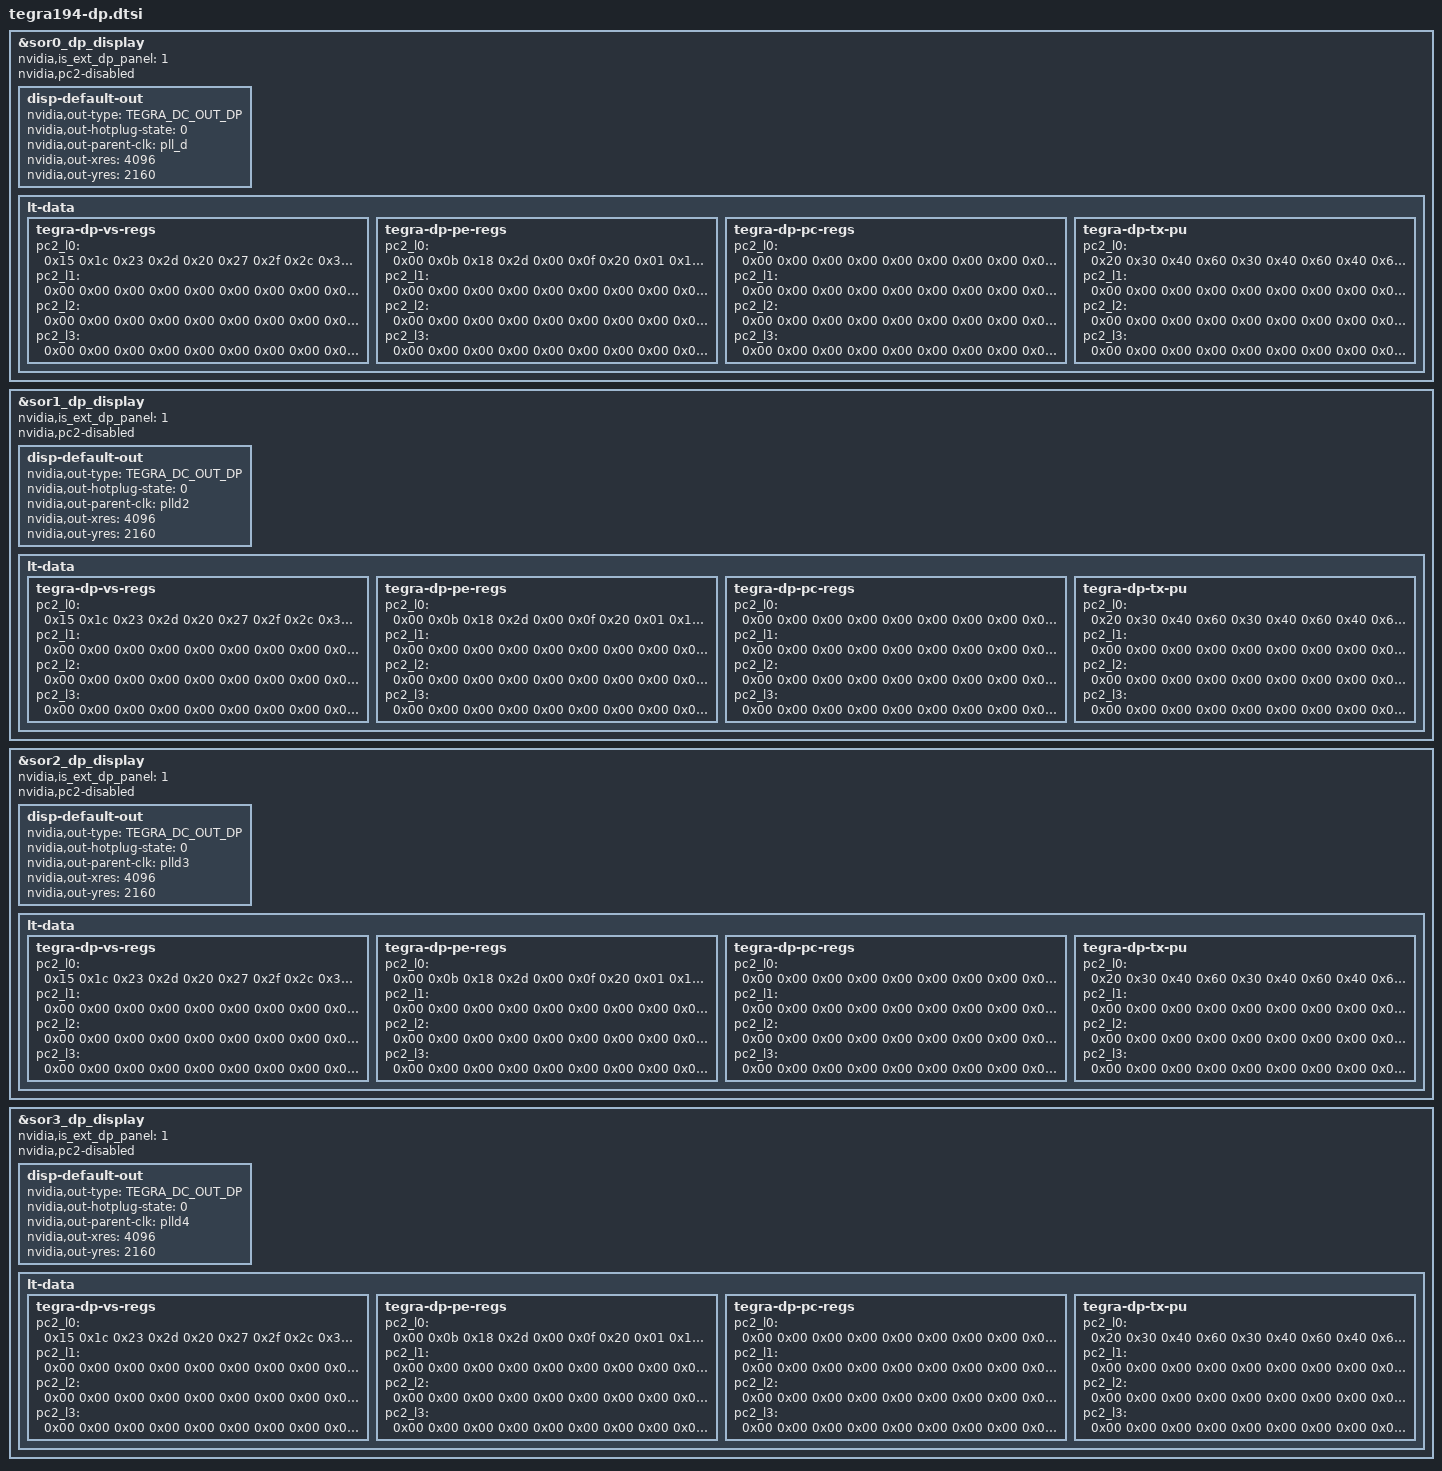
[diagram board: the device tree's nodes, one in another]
/*
 * tegra194-dp.dtsi:
 *
 * Copyright (c) 2017, NVIDIA CORPORATION.  All rights reserved.
 *
 * This program is free software; you can redistribute it and/or modify
 * it under the terms of the GNU General Public License as published by
 * the Free Software Foundation; version 2 of the License.
 *
 * This program is distributed in the hope that it will be useful, but WITHOUT
 * ANY WARRANTY; without even the implied warranty of MERCHANTABILITY or
 * FITNESS FOR A PARTICULAR PURPOSE.  See the GNU General Public License for
 * more details.
 */

#include <dt-bindings/display/tegra-dc.h>

&sor0_dp_display {
	nvidia,is_ext_dp_panel = <1>;
	nvidia,pc2-disabled;
	disp-default-out {
		nvidia,out-type = <TEGRA_DC_OUT_DP>;
		nvidia,out-hotplug-state = <0>;
		nvidia,out-parent-clk = "pll_d";
		nvidia,out-xres = <4096>;
		nvidia,out-yres = <2160>;
	};
	/* Setting for LT data */
	lt-data {
		tegra-dp-vs-regs {
			/* postcursor2 L0 */
			pc2_l0 = <
				/* pre-emphasis: L0, L1, L2, L3 */
				0x15 0x1c 0x23 0x2d /* voltage swing: L0 */
				0x20 0x27 0x2f /* L1 */
				0x2c 0x36 /* L2 */
				0x3c /* L3 */
			>;
			/* postcursor2 L1 - UNUSED */
			pc2_l1 = <
				0x00 0x00 0x00 0x00
				0x00 0x00 0x00
				0x00 0x00
				0x00
			>;
			/* postcursor2 L2 - UNUSED */
			pc2_l2 = <
				0x00 0x00 0x00 0x00
				0x00 0x00 0x00
				0x00 0x00
				0x00
			>;
			/* postcursor2 L3 - UNUSED */
			pc2_l3 = <
				0x00 0x00 0x00 0x00
				0x00 0x00 0x00
				0x00 0x00
				0x00
			>;
		};
		tegra-dp-pe-regs {
			/* postcursor2 L0 */
			pc2_l0 = <
				/* pre-emphasis: L0, L1, L2, L3 */
				0x00 0x0b 0x18 0x2d /* voltage swing: L0 */
				0x00 0x0f 0x20 /* L1 */
				0x01 0x18 /* L2 */
				0x00 /* L3 */
			>;
			/* postcursor2 L1 - UNUSED */
			pc2_l1 = <
				0x00 0x00 0x00 0x00
				0x00 0x00 0x00
				0x00 0x00
				0x00
			>;
			/* postcursor2 L2 - UNUSED */
			pc2_l2 = <
				0x00 0x00 0x00 0x00
				0x00 0x00 0x00
				0x00 0x00
				0x00
			>;
			/* postcursor2 L3 - UNUSED */
			pc2_l3 = <
				0x00 0x00 0x00 0x00
				0x00 0x00 0x00
				0x00 0x00
				0x00
			>;
		};
		tegra-dp-pc-regs {
			/* postcursor2 L0 */
			pc2_l0 = <
				/* pre-emphasis: L0, L1, L2, L3 */
				0x00 0x00 0x00 0x00 /* voltage swing: L0 */
				0x00 0x00 0x00 /* L1 */
				0x00 0x00 /* L2 */
				0x00 /* L3 */
			>;
			/* postcursor2 L1 - UNUSED */
			pc2_l1 = <
				0x00 0x00 0x00 0x00
				0x00 0x00 0x00
				0x00 0x00
				0x00
			>;
			/* postcursor2 L2 - UNUSED */
			pc2_l2 = <
				0x00 0x00 0x00 0x00
				0x00 0x00 0x00
				0x00 0x00
				0x00
			>;
			/* postcursor2 L3 - UNUSED */
			pc2_l3 = <
				0x00 0x00 0x00 0x00
				0x00 0x00 0x00
				0x00 0x00
				0x00
			>;
		};
		tegra-dp-tx-pu {
			/* postcursor2 L0 */
			pc2_l0 = <
				/* pre-emphasis: L0, L1, L2, L3 */
				0x20 0x30 0x40 0x60 /* voltage swing: L0 */
				0x30 0x40 0x60 /* L1 */
				0x40 0x60 /* L2 */
				0x60 /* L3 */
			>;
			/* postcursor2 L1 - UNUSED */
			pc2_l1 = <
				0x00 0x00 0x00 0x00
				0x00 0x00 0x00
				0x00 0x00
				0x00
			>;
			/* postcursor2 L2 - UNUSED */
			pc2_l2 = <
				0x00 0x00 0x00 0x00
				0x00 0x00 0x00
				0x00 0x00
				0x00
			>;
			/* postcursor2 L3 - UNUSED */
			pc2_l3 = <
				0x00 0x00 0x00 0x00
				0x00 0x00 0x00
				0x00 0x00
				0x00
			>;
		};
	};//lt-data;
};

&sor1_dp_display {
	nvidia,is_ext_dp_panel = <1>;
	nvidia,pc2-disabled;
	disp-default-out {
		nvidia,out-type = <TEGRA_DC_OUT_DP>;
		nvidia,out-hotplug-state = <0>;
		nvidia,out-parent-clk = "plld2";
		nvidia,out-xres = <4096>;
		nvidia,out-yres = <2160>;
	};
	/* Setting for LT data */
	lt-data {
		tegra-dp-vs-regs {
			/* postcursor2 L0 */
			pc2_l0 = <
				/* pre-emphasis: L0, L1, L2, L3 */
				0x15 0x1c 0x23 0x2d /* voltage swing: L0 */
				0x20 0x27 0x2f /* L1 */
				0x2c 0x36 /* L2 */
				0x3c /* L3 */
			>;
			/* postcursor2 L1 - UNUSED */
			pc2_l1 = <
				0x00 0x00 0x00 0x00
				0x00 0x00 0x00
				0x00 0x00
				0x00
			>;
			/* postcursor2 L2 - UNUSED */
			pc2_l2 = <
				0x00 0x00 0x00 0x00
				0x00 0x00 0x00
				0x00 0x00
				0x00
			>;
			/* postcursor2 L3 - UNUSED */
			pc2_l3 = <
				0x00 0x00 0x00 0x00
				0x00 0x00 0x00
				0x00 0x00
				0x00
			>;
		};
		tegra-dp-pe-regs {
			/* postcursor2 L0 */
			pc2_l0 = <
				/* pre-emphasis: L0, L1, L2, L3 */
				0x00 0x0b 0x18 0x2d /* voltage swing: L0 */
				0x00 0x0f 0x20 /* L1 */
				0x01 0x18 /* L2 */
				0x00 /* L3 */
			>;
			/* postcursor2 L1 - UNUSED */
			pc2_l1 = <
				0x00 0x00 0x00 0x00
				0x00 0x00 0x00
				0x00 0x00
				0x00
			>;
			/* postcursor2 L2 - UNUSED */
			pc2_l2 = <
				0x00 0x00 0x00 0x00
				0x00 0x00 0x00
				0x00 0x00
				0x00
			>;
			/* postcursor2 L3 - UNUSED */
			pc2_l3 = <
				0x00 0x00 0x00 0x00
				0x00 0x00 0x00
				0x00 0x00
				0x00
			>;
		};
		tegra-dp-pc-regs {
			/* postcursor2 L0 */
			pc2_l0 = <
				/* pre-emphasis: L0, L1, L2, L3 */
				0x00 0x00 0x00 0x00 /* voltage swing: L0 */
				0x00 0x00 0x00 /* L1 */
				0x00 0x00 /* L2 */
				0x00 /* L3 */
			>;
			/* postcursor2 L1 - UNUSED */
			pc2_l1 = <
				0x00 0x00 0x00 0x00
				0x00 0x00 0x00
				0x00 0x00
				0x00
			>;
			/* postcursor2 L2 - UNUSED */
			pc2_l2 = <
				0x00 0x00 0x00 0x00
				0x00 0x00 0x00
				0x00 0x00
				0x00
			>;
			/* postcursor2 L3 - UNUSED */
			pc2_l3 = <
				0x00 0x00 0x00 0x00
				0x00 0x00 0x00
				0x00 0x00
				0x00
			>;
		};
		tegra-dp-tx-pu {
			/* postcursor2 L0 */
			pc2_l0 = <
				/* pre-emphasis: L0, L1, L2, L3 */
				0x20 0x30 0x40 0x60 /* voltage swing: L0 */
				0x30 0x40 0x60 /* L1 */
				0x40 0x60 /* L2 */
				0x60 /* L3 */
			>;
			/* postcursor2 L1 - UNUSED */
			pc2_l1 = <
				0x00 0x00 0x00 0x00
				0x00 0x00 0x00
				0x00 0x00
				0x00
			>;
			/* postcursor2 L2 - UNUSED */
			pc2_l2 = <
				0x00 0x00 0x00 0x00
				0x00 0x00 0x00
				0x00 0x00
				0x00
			>;
			/* postcursor2 L3 - UNUSED */
			pc2_l3 = <
				0x00 0x00 0x00 0x00
				0x00 0x00 0x00
				0x00 0x00
				0x00
			>;
		};
	};//lt-data;
};

&sor2_dp_display {
	nvidia,is_ext_dp_panel = <1>;
	nvidia,pc2-disabled;
	disp-default-out {
		nvidia,out-type = <TEGRA_DC_OUT_DP>;
		nvidia,out-hotplug-state = <0>;
		nvidia,out-parent-clk = "plld3";
		nvidia,out-xres = <4096>;
		nvidia,out-yres = <2160>;
	};
	/* Setting for LT data */
	lt-data {
		tegra-dp-vs-regs {
			/* postcursor2 L0 */
			pc2_l0 = <
				/* pre-emphasis: L0, L1, L2, L3 */
				0x15 0x1c 0x23 0x2d /* voltage swing: L0 */
				0x20 0x27 0x2f /* L1 */
				0x2c 0x36 /* L2 */
				0x3c /* L3 */
			>;
			/* postcursor2 L1 - UNUSED */
			pc2_l1 = <
				0x00 0x00 0x00 0x00
				0x00 0x00 0x00
				0x00 0x00
				0x00
			>;
			/* postcursor2 L2 - UNUSED */
			pc2_l2 = <
				0x00 0x00 0x00 0x00
				0x00 0x00 0x00
				0x00 0x00
				0x00
			>;
			/* postcursor2 L3 - UNUSED */
			pc2_l3 = <
				0x00 0x00 0x00 0x00
				0x00 0x00 0x00
				0x00 0x00
				0x00
			>;
		};
		tegra-dp-pe-regs {
			/* postcursor2 L0 */
			pc2_l0 = <
				/* pre-emphasis: L0, L1, L2, L3 */
				0x00 0x0b 0x18 0x2d /* voltage swing: L0 */
				0x00 0x0f 0x20 /* L1 */
				0x01 0x18 /* L2 */
				0x00 /* L3 */
			>;
			/* postcursor2 L1 - UNUSED */
			pc2_l1 = <
				0x00 0x00 0x00 0x00
				0x00 0x00 0x00
				0x00 0x00
				0x00
			>;
			/* postcursor2 L2 - UNUSED */
			pc2_l2 = <
				0x00 0x00 0x00 0x00
				0x00 0x00 0x00
				0x00 0x00
				0x00
			>;
			/* postcursor2 L3 - UNUSED */
			pc2_l3 = <
				0x00 0x00 0x00 0x00
				0x00 0x00 0x00
				0x00 0x00
				0x00
			>;
		};
		tegra-dp-pc-regs {
			/* postcursor2 L0 */
			pc2_l0 = <
				/* pre-emphasis: L0, L1, L2, L3 */
				0x00 0x00 0x00 0x00 /* voltage swing: L0 */
				0x00 0x00 0x00 /* L1 */
				0x00 0x00 /* L2 */
				0x00 /* L3 */
			>;
			/* postcursor2 L1 - UNUSED */
			pc2_l1 = <
				0x00 0x00 0x00 0x00
				0x00 0x00 0x00
				0x00 0x00
				0x00
			>;
			/* postcursor2 L2 - UNUSED */
			pc2_l2 = <
				0x00 0x00 0x00 0x00
				0x00 0x00 0x00
				0x00 0x00
				0x00
			>;
			/* postcursor2 L3 - UNUSED */
			pc2_l3 = <
				0x00 0x00 0x00 0x00
				0x00 0x00 0x00
				0x00 0x00
				0x00
			>;
		};
		tegra-dp-tx-pu {
			/* postcursor2 L0 */
			pc2_l0 = <
				/* pre-emphasis: L0, L1, L2, L3 */
				0x20 0x30 0x40 0x60 /* voltage swing: L0 */
				0x30 0x40 0x60 /* L1 */
				0x40 0x60 /* L2 */
				0x60 /* L3 */
			>;
			/* postcursor2 L1 - UNUSED */
			pc2_l1 = <
				0x00 0x00 0x00 0x00
				0x00 0x00 0x00
				0x00 0x00
				0x00
			>;
			/* postcursor2 L2 - UNUSED */
			pc2_l2 = <
				0x00 0x00 0x00 0x00
				0x00 0x00 0x00
				0x00 0x00
				0x00
			>;
			/* postcursor2 L3 - UNUSED */
			pc2_l3 = <
				0x00 0x00 0x00 0x00
				0x00 0x00 0x00
				0x00 0x00
				0x00
			>;
		};
	};//lt-data;
};

&sor3_dp_display {
	nvidia,is_ext_dp_panel = <1>;
	nvidia,pc2-disabled;
	disp-default-out {
		nvidia,out-type = <TEGRA_DC_OUT_DP>;
		nvidia,out-hotplug-state = <0>;
		nvidia,out-parent-clk = "plld4";
		nvidia,out-xres = <4096>;
		nvidia,out-yres = <2160>;
	};
	/* Setting for LT data */
	lt-data {
		tegra-dp-vs-regs {
			/* postcursor2 L0 */
			pc2_l0 = <
				/* pre-emphasis: L0, L1, L2, L3 */
				0x15 0x1c 0x23 0x2d /* voltage swing: L0 */
				0x20 0x27 0x2f /* L1 */
				0x2c 0x36 /* L2 */
				0x3c /* L3 */
			>;
			/* postcursor2 L1 - UNUSED */
			pc2_l1 = <
				0x00 0x00 0x00 0x00
				0x00 0x00 0x00
				0x00 0x00
				0x00
			>;
			/* postcursor2 L2 - UNUSED */
			pc2_l2 = <
				0x00 0x00 0x00 0x00
				0x00 0x00 0x00
				0x00 0x00
				0x00
			>;
			/* postcursor2 L3 - UNUSED */
			pc2_l3 = <
				0x00 0x00 0x00 0x00
				0x00 0x00 0x00
				0x00 0x00
				0x00
			>;
		};
		tegra-dp-pe-regs {
			/* postcursor2 L0 */
			pc2_l0 = <
				/* pre-emphasis: L0, L1, L2, L3 */
				0x00 0x0b 0x18 0x2d /* voltage swing: L0 */
				0x00 0x0f 0x20 /* L1 */
				0x01 0x18 /* L2 */
				0x00 /* L3 */
			>;
			/* postcursor2 L1 - UNUSED */
			pc2_l1 = <
				0x00 0x00 0x00 0x00
				0x00 0x00 0x00
				0x00 0x00
				0x00
			>;
			/* postcursor2 L2 - UNUSED */
			pc2_l2 = <
				0x00 0x00 0x00 0x00
				0x00 0x00 0x00
				0x00 0x00
				0x00
			>;
			/* postcursor2 L3 - UNUSED */
			pc2_l3 = <
				0x00 0x00 0x00 0x00
				0x00 0x00 0x00
				0x00 0x00
				0x00
			>;
		};
		tegra-dp-pc-regs {
			/* postcursor2 L0 */
			pc2_l0 = <
				/* pre-emphasis: L0, L1, L2, L3 */
				0x00 0x00 0x00 0x00 /* voltage swing: L0 */
				0x00 0x00 0x00 /* L1 */
				0x00 0x00 /* L2 */
				0x00 /* L3 */
			>;
			/* postcursor2 L1 - UNUSED */
			pc2_l1 = <
				0x00 0x00 0x00 0x00
				0x00 0x00 0x00
				0x00 0x00
				0x00
			>;
			/* postcursor2 L2 - UNUSED */
			pc2_l2 = <
				0x00 0x00 0x00 0x00
				0x00 0x00 0x00
				0x00 0x00
				0x00
			>;
			/* postcursor2 L3 - UNUSED */
			pc2_l3 = <
				0x00 0x00 0x00 0x00
				0x00 0x00 0x00
				0x00 0x00
				0x00
			>;
		};
		tegra-dp-tx-pu {
			/* postcursor2 L0 */
			pc2_l0 = <
				/* pre-emphasis: L0, L1, L2, L3 */
				0x20 0x30 0x40 0x60 /* voltage swing: L0 */
				0x30 0x40 0x60 /* L1 */
				0x40 0x60 /* L2 */
				0x60 /* L3 */
			>;
			/* postcursor2 L1 - UNUSED */
			pc2_l1 = <
				0x00 0x00 0x00 0x00
				0x00 0x00 0x00
				0x00 0x00
				0x00
			>;
			/* postcursor2 L2 - UNUSED */
			pc2_l2 = <
				0x00 0x00 0x00 0x00
				0x00 0x00 0x00
				0x00 0x00
				0x00
			>;
			/* postcursor2 L3 - UNUSED */
			pc2_l3 = <
				0x00 0x00 0x00 0x00
				0x00 0x00 0x00
				0x00 0x00
				0x00
			>;
		};
	};//lt-data;
};
